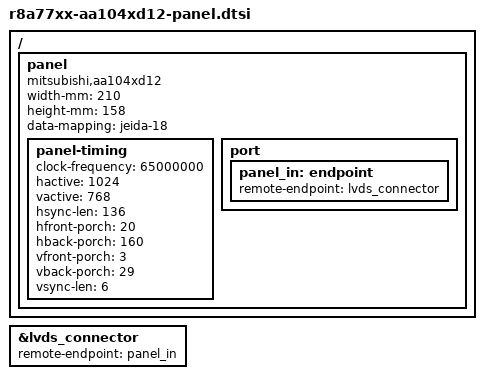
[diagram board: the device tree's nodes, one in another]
// SPDX-License-Identifier: GPL-2.0
/*
 * Common file for the AA104XD12 panel connected to Renesas R-Car boards
 *
 * Copyright (C) 2014 Renesas Electronics Corp.
 */

/ {
	panel {
		compatible = "mitsubishi,aa104xd12", "panel-lvds";

		width-mm = <210>;
		height-mm = <158>;
		data-mapping = "jeida-18";

		panel-timing {
			/* 1024x768 @65Hz */
			clock-frequency = <65000000>;
			hactive = <1024>;
			vactive = <768>;
			hsync-len = <136>;
			hfront-porch = <20>;
			hback-porch = <160>;
			vfront-porch = <3>;
			vback-porch = <29>;
			vsync-len = <6>;
		};

		port {
			panel_in: endpoint {
				remote-endpoint = <&lvds_connector>;
			};
		};
	};
};

&lvds_connector {
	remote-endpoint = <&panel_in>;
};
